# freechips_rocketchip_unknown register map
File version: 0.1
From freechips,rocketchip-unknown,model device generator
Registers are 32-bit, read-write, no defined reset value unless marked. A register's access mark holds for its fields unless they carry their own. Offsets are from the block's base; lines under a group give offsets from that group; [hi:lo] are bit positions; {n}, {i} and the like mark numbered series; 'fields as' and 'values as' point back to an identical list; <NAME> marks a mode.

## Memory map
0x02000000 riscv_clint0_0 size 0x10000 — From riscv,clint0,control peripheral generator
0x0C000000 riscv_plic0_0 size 0x4000000 — From riscv,plic0,control peripheral generator
0x54000000 sifive_uart0_0 size 0x1000 — From sifive,uart0,control peripheral generator

## riscv_clint0_0 — From riscv,clint0,control peripheral generator
Base 0x02000000
0x00 msip_0 — MSIP Register for hart 0
0x4000 mtimecmp_0 64-bit — MTIMECMP Register for hart 0
0xBFF8 mtime 64-bit

## riscv_plic0_0 — From riscv,plic0,control peripheral generator
Base 0x0C000000
{0x0+4i} priority_{i} (i=1..273) — PRIORITY Register for interrupt id {i}
{0x1000+4i} pending_{i} (i=0..7) — PENDING Register for interrupt ids {32i+31} to {32i}
0x1020 pending_8 — PENDING Register for interrupt ids 273 to 256
{0x2000+4i} enable_{i}_0 (i=0..7) — ENABLE Register for interrupt ids {32i+31} to {32i} for hart 0
0x2020 enable_8_0 — ENABLE Register for interrupt ids 273 to 256 for hart 0
0x200000 threshold_0 — PRIORITY THRESHOLD Register for hart 0
0x200004 claimplete_0 — CLAIM and COMPLETE Register for hart 0

## sifive_uart0_0 — From sifive,uart0,control peripheral generator
Base 0x54000000
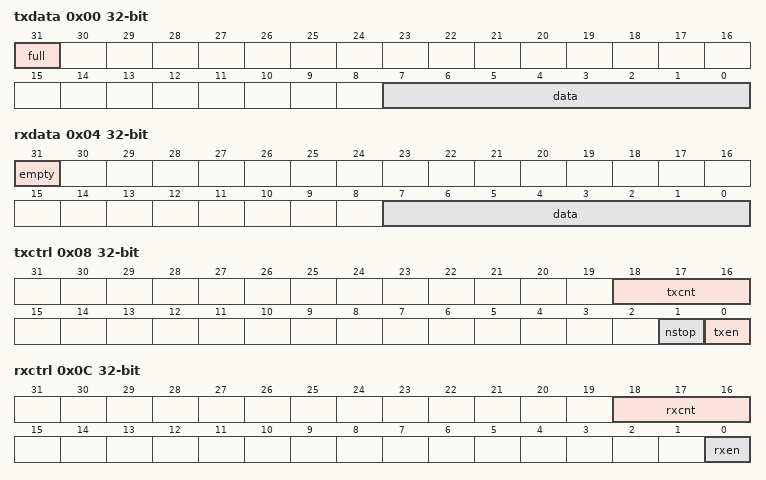
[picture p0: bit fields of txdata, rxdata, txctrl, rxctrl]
0x00 txdata — Transmit data register
  [31] full ro — Transmit FIFO full
  [7:0] data — Transmit data
0x04 rxdata — Receive data register
  [31] empty ro — Receive FIFO empty
  [7:0] data ro — Received data
0x08 txctrl — Transmit control register
  [18:16] txcnt — Transmit watermark level
  [1] nstop — Number of stop bits
  [0] txen — Transmit enable
0x0C rxctrl — Receive control register
  [18:16] rxcnt — Receive watermark level
  [0] rxen — Receive enable
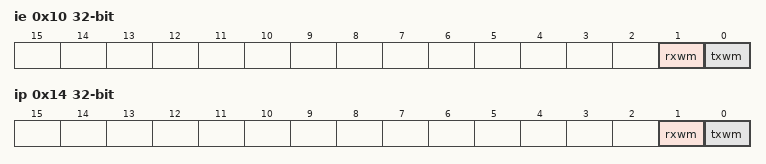
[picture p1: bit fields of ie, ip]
0x10 ie — UART interrupt enable
  [1] rxwm — Receive watermark interrupt enable
  [0] txwm — Transmit watermark interrupt enable
0x14 ip — UART interrupt pending
  [1] rxwm ro — Receive watermark interrupt pending
  [0] txwm ro — Transmit watermark interrupt pending
0x18 div — Baud rate divisor
  [15:0] div — Baud rate divisor.
